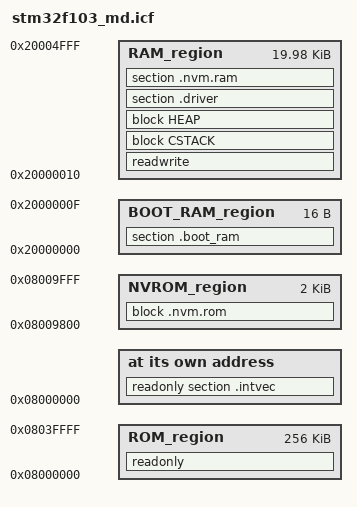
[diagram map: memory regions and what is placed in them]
/*###ICF### Section handled by ICF editor, don't touch! ****/
/*-Editor annotation file-*/
/* IcfEditorFile="$PROJ_DIR$\cortex_v1_0.xml" */
/*-Specials-*/
define symbol __ICFEDIT_intvec_start__ = 0x08000000;
/*-Memory Regions-*/
define symbol __ICFEDIT_region_ROM_start__   = 0x08000000;
define symbol __ICFEDIT_region_ROM_end__     = 0x0803FFFF;
define symbol __ICFEDIT_region_NVROM_start__ = 0x08009800;
define symbol __ICFEDIT_region_NVROM_end__   = 0x08009FFF;
define symbol __ICFEDIT_region_RAM_start__   = 0x20000010;
define symbol __ICFEDIT_region_RAM_end__     = 0x20004FFF;
/*-Sizes-*/
define symbol __ICFEDIT_size_cstack__ = 0x7F0;
define symbol __ICFEDIT_size_heap__   = 0x2000;
define symbol __ICFEDIT_size_nvm__    = 0x400;
/**** End of ICF editor section. ###ICF###*/


define memory mem with size = 4G;
define region ROM_region   = mem:[from __ICFEDIT_region_ROM_start__   to __ICFEDIT_region_ROM_end__];
define region NVROM_region = mem:[from __ICFEDIT_region_NVROM_start__ to __ICFEDIT_region_NVROM_end__];
define region RAM_region   = mem:[from __ICFEDIT_region_RAM_start__   to __ICFEDIT_region_RAM_end__];
define region BOOT_RAM_region     = mem:[from 0x20000000 to 0x2000000F];

define block CSTACK    with alignment = 8, size = __ICFEDIT_size_cstack__   { };
define block HEAP      with alignment = 8, size = __ICFEDIT_size_heap__     { };

initialize by copy { readwrite };
do not initialize  { section .noinit };

place at address mem:__ICFEDIT_intvec_start__ { readonly section .intvec };

place in ROM_region   { readonly };
place in RAM_region   { readwrite,
                        block CSTACK, block HEAP };

/* place in RAM_region   { section shell_cmd }; */
keep { section shell_cmd };
keep { section FSymTab };
keep { section VSymTab };

place in RAM_region   { section .driver };
keep { section .driver };

/* board hardware init */
/* place in RAM_region   { section board_init }; */
keep { section board_init };

/* library or component init */
/* place in RAM_region   { section lib_init }; */
keep { section component_init };

/* application init */
/* place in RAM_region   { section task_init }; */
keep { section task_init };

/* os background time schedule define */
/* place in RAM_region   { section os_bg }; */
keep { section os_bg };
/* place in RAM_region   { section os_bg_1ms }; */
keep { section os_bg_1ms };
/* place in RAM_region   { section os_bg_4ms }; */
keep { section os_bg_4ms };
/* place in RAM_region   { section os_bg_8ms }; */
keep { section os_bg_8ms };
/* place in RAM_region   { section os_bg_16ms }; */
keep { section os_bg_16ms };

/* os foreground time schedule define */
/* place in RAM_region   { section os_fg_1ms }; */
keep { section os_fg_1ms };
/* place in RAM_region   { section os_fg_4ms }; */
keep { section os_fg_4ms };
/* place in RAM_region   { section os_fg_8ms }; */
keep { section os_fg_8ms };
/* place in RAM_region   { section os_fg_16ms }; */
keep { section os_fg_16ms };

/*nvm support*/
place in RAM_region   { section .nvm.ram };
keep { section .nvm.ram };
define block .nvm.rom      with alignment = 0x400, size = __ICFEDIT_size_nvm__ * 2     { };
keep { block .nvm.rom };
place in NVROM_region   { block .nvm.rom };

/* boot and application shared ram support */
place in BOOT_RAM_region   {section .boot_ram };
do not initialize  { section .boot_ram };
keep { section .boot_ram };
